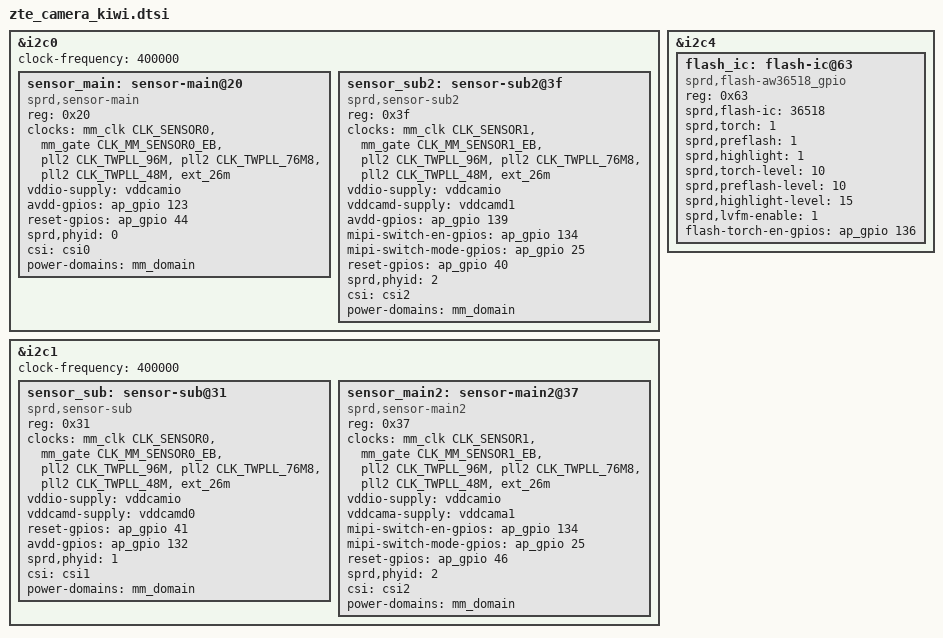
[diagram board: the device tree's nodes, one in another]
&i2c0 {
	/delete-node/ sensor-main@20;
};

&i2c0 {
	/delete-node/ sensor-sub@5a;
};

&i2c1 {
	/delete-node/ sensor-sub2@6e;
};

&i2c1 {
	/delete-node/ sensor-main2@20;
};

&i2c1 {
	/delete-node/ sensor-main3@6c;
};
&i2c0 {
	status = "okay";
	clock-frequency = <400000>;

	// main camera: HI5021Q 50M
	sensor_main: sensor-main@20 {
		compatible = "sprd,sensor-main";
		reg = <0x20>;
		clock-names = "clk_src","sensor_eb",
			"clk_96m","clk_76m8",
			"clk_48m","clk_26m";
		clocks = <&mm_clk CLK_SENSOR0>,<&mm_gate CLK_MM_SENSOR0_EB>,
				<&pll2 CLK_TWPLL_96M>,<&pll2 CLK_TWPLL_76M8>,
				<&pll2 CLK_TWPLL_48M>,<&ext_26m>;
		vddio-supply = <&vddcamio>;
		//vddcammot-supply = <&vddcammot>;
		avdd-gpios=<&ap_gpio 123 0>;
		reset-gpios = <&ap_gpio 44 0>;
		sprd,phyid = <0>;
		csi = <&csi0>; //dcam
		power-domains = <&mm_domain>;
	};

	//macro: GC5035 5M
	sensor_sub2: sensor-sub2@3f {
		compatible = "sprd,sensor-sub2";
		reg = <0x3f>;
		clock-names = "clk_src","sensor_eb",
			"clk_96m","clk_76m8",
			"clk_48m","clk_26m";
		clocks = <&mm_clk CLK_SENSOR1>,<&mm_gate CLK_MM_SENSOR1_EB>,
			<&pll2 CLK_TWPLL_96M>,<&pll2 CLK_TWPLL_76M8>,
			<&pll2 CLK_TWPLL_48M>,<&ext_26m>;
		vddio-supply = <&vddcamio>;
		vddcamd-supply = <&vddcamd1>;
		avdd-gpios=<&ap_gpio 139 0>;
		mipi-switch-en-gpios = <&ap_gpio 134 0>;
		mipi-switch-mode-gpios = <&ap_gpio 25 0>;
		reset-gpios = <&ap_gpio 40 0>;
		sprd,phyid = <2>;
		csi = <&csi2>;
		power-domains = <&mm_domain>;
	};
};

&i2c1 {
	status = "okay";
	clock-frequency = <400000>;

	// front camera: GC08A3 8M & HI846 8M
	sensor_sub: sensor-sub@31{
		compatible = "sprd,sensor-sub";
		reg = <0x31>;
		clock-names = "clk_src","sensor_eb",
			"clk_96m","clk_76m8",
			"clk_48m","clk_26m";
		clocks = <&mm_clk CLK_SENSOR0>,<&mm_gate CLK_MM_SENSOR0_EB>,
				<&pll2 CLK_TWPLL_96M>,<&pll2 CLK_TWPLL_76M8>,
				<&pll2 CLK_TWPLL_48M>,<&ext_26m>;

		vddio-supply = <&vddcamio>;
		vddcamd-supply = <&vddcamd0>;
		reset-gpios = <&ap_gpio 41 0>;
		avdd-gpios=<&ap_gpio 132 0>;
		sprd,phyid = <1>;//csi2 4LANE
		csi = <&csi1>;
		power-domains = <&mm_domain>;
	};

	//DEPTH: GC02M1B 2M
	sensor_main2: sensor-main2@37 {
		compatible = "sprd,sensor-main2";
		reg = <0x37>;
		clock-names = "clk_src","sensor_eb",
			"clk_96m","clk_76m8",
			"clk_48m","clk_26m";
		clocks = <&mm_clk CLK_SENSOR1>,<&mm_gate CLK_MM_SENSOR1_EB>,
			<&pll2 CLK_TWPLL_96M>,<&pll2 CLK_TWPLL_76M8>,
			<&pll2 CLK_TWPLL_48M>,<&ext_26m>;
		vddio-supply = <&vddcamio>;
		vddcama-supply = <&vddcama1>;
		//vddcamd-supply = <&vddcamio>;
		mipi-switch-en-gpios = <&ap_gpio 134 0>;
		mipi-switch-mode-gpios = <&ap_gpio 25 0>;
		reset-gpios = <&ap_gpio 46 0>;
		sprd,phyid = <2>;//csi1
		csi = <&csi2>;
		power-domains = <&mm_domain>;
	};
};
&i2c4 {
	/delete-node/ flash-ic@63;
};
&i2c4 {
	flash_ic: flash-ic@63 {
		compatible = "sprd,flash-aw36518_gpio";
		reg = <0x63>;
		sprd,flash-ic = <36518>;
		sprd,torch = <1>;
		sprd,preflash = <1>;
		sprd,highlight = <1>;
		sprd,torch-level = <10>;
		sprd,preflash-level = <10>;
		sprd,highlight-level = <15>;
		sprd,lvfm-enable = <1>;
		flash-torch-en-gpios = <&ap_gpio 136 0>;
	};
};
